# ESP32-S31 register map
Vendor: ESPRESSIF SYSTEMS (SHANGHAI) CO., LTD.; Series: ESP32 S-Series; File version: 1
CPU: RV32IMAFC r0p0, little endian, no MPU, FPU, 0 interrupt priority bits
Address unit: 32 bits
Registers are 32-bit, read-write, reset 0x0 unless marked. A register's access mark holds for its fields unless they carry their own. Offsets are from the block's base; [hi:lo] are bit positions; <NAME> marks a mode.

## GMAC (part 1 of 2) — Ethernet MAC
Base 0x20350000
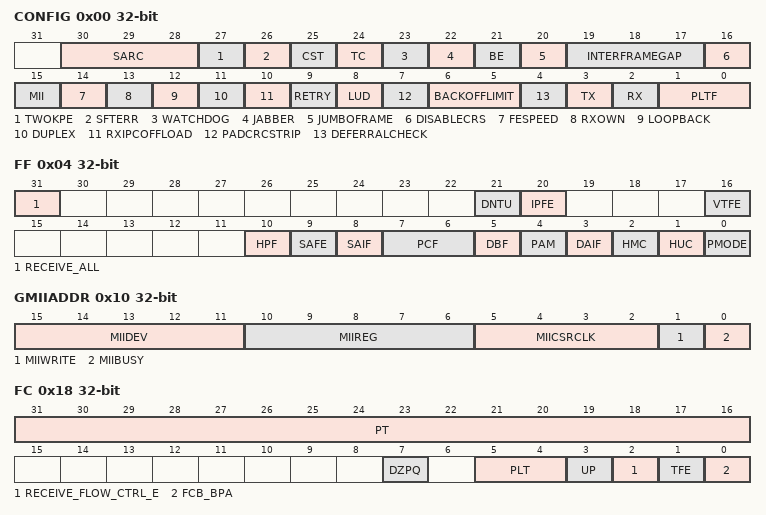
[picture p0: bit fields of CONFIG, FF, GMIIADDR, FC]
0x00 CONFIG — MAC configuration
  [30:28] SARC — Source Address Insertion or Replacement Control This field controls the source address insertion or replacement for all transmitted frames Bit 30 specifies which MAC Address register _0 or 1_ is used for source address insertion or replacement based on the values of Bits [29:28]: 2'b0x: The input signals mti_sa_ctrl_i and ati_sa_ctrl_i control the SA field generation 2'b10: If Bit 30 is set to 0, the MAC inserts the content of the MAC Address 0 registers _registers 16 and 17_ in the SA field of all transmitted frames If Bit 30 is set to 1 and the Enable MAC Address Register 1 option is selected during core configuration, the MAC inserts the content of the MAC Address 1 registers _registers 18 and 19_ in the SA field of all transmitted frames 2'b11: If Bit 30 is set to 0, the MAC replaces the content of the MAC Address 0 registers _registers 16 and 17_ in the SA field of all transmitted frames If Bit 30 is set to 1 and the Enable MAC Address Register 1 option is selected during core configuration, the MAC replaces the content of the MAC Address 1 registers _registers 18 and 19_ in the SA field of all transmitted frames Note: Changes to this field take effect only on the start of a frame If you write this register field when a frame is being transmitted, only the subsequent frame can use the updated value, that is, the current frame does not use the updated value These bits are reserved and RO when the Enable SA, VLAN, and CRC Insertion on TX feature is not selected during core configuration
  [27] TWOKPE — IEEE 8023as Support for 2K Packets When set, the MAC considers all frames, with up to 2,000 bytes length, as normal packets When Bit 20 _JE_ is not set, the MAC considers all received frames of size more than 2K bytes as Giant frames When this bit is reset and Bit 20 _JE_ is not set, the MAC considers all received frames of size more than 1,518 bytes _1,522 bytes for tagged_ as Giant frames When Bit 20 is set, setting this bit has no effect on Giant Frame status For more information about how the setting of this bit and Bit 20 impact the Giant frame status, see Table 631
  [26] SFTERR — SMII Force Transmit Error When set, this bit indicates to the PHY to force a transmit error in the SMII frame being transmitted This bit is reserved if the SMII PHY port is not selected during core configuration
  [25] CST — CRC Stripping for Type Frames When this bit is set, the last 4 bytes _FCS_ of all frames of Ether type _Length/Type field greater than or equal to 1,536_ are stripped and dropped before forwarding the frame to the application This function is not valid when the IP Checksum Engine _Type 1_ is enabled in the MAC receiver This function is valid when Type 2 Checksum Offload Engine is enabled Note: For information about how the settings of Bit 7 _ACS_ and this bit impact the frame length, see Table 632
  [24] TC — Transmit Configuration in RGMII, SGMII, or SMII When set, this bit enables the transmission of duplex mode, link speed, and link up or down information to the PHY in the RGMII, SMII, or SGMII port When this bit is reset, no such information is driven to the PHY This bit is reserved _and RO_ if the RGMII, SMII, or SGMII PHY port is not selected during core configuration The details of this feature are explained in the following sections: “Reduced Gigabit Media Independent Interface” on page 249 “Serial Media Independent Interface” on page 245 “Serial Gigabit Media Independent Interface” on page 257
  [23] WATCHDOG — Watchdog Disable When this bit is set, the MAC disables the watchdog timer on the receiver The MAC can receive frames of up to 16,383 bytes When this bit is reset, the MAC does not allow a receive frame which more than 2,048 bytes _10,240 if JE is set high_ or the value programmed in Register 55 _Watchdog Timeout Register_ The MAC cuts off any bytes received after the watchdog limit number of bytes
  [22] JABBER — Jabber Disable When this bit is set, the MAC disables the jabber timer on the transmitter The MAC can transfer frames of up to 16,383 bytes When this bit is reset, the MAC cuts off the transmitter if the application sends out more than 2,048 bytes of data _10,240 if JE is set high_ during transmission
  [21] BE — Frame Burst Enable When this bit is set, the MAC allows frame bursting during transmission in the GMII halfduplex mode This bit is reserved _and RO_ in the 10/100 Mbps only or fullduplexonly configurations
  [20] JUMBOFRAME — Jumbo Frame Enable When this bit is set, the MAC allows Jumbo frames of 9,018 bytes _9,022 bytes for VLAN tagged frames_ without reporting a giant frame error in the receive frame status
  [19:17] INTERFRAMEGAP — InterFrame Gap These bits control the minimum IFG between frames during transmission 000: 96 bit times 001: 88 bit times 010: 80 bit times 111: 40 bit times In the halfduplex mode, the minimum IFG can be configured only for 64 bit times _IFG = 100_ Lower values are not considered In the 1000Mbps mode, the minimum IFG supported is 64 bit times _and above_ in the GMACCORE configuration and 80 bit times _and above_ in other configurations When a JAM pattern is being transmitted because of backpressure activation, the MAC does not consider the minimum IFG
  [16] DISABLECRS — Disable Carrier Sense During Transmission When set high, this bit makes the MAC transmitter ignore the _G_MII CRS signal during frame transmission in the halfduplex mode This request results in no errors generated because of Loss of Carrier or No Carrier during such transmission When this bit is low, the MAC transmitter generates such errors because of Carrier Sense and can even abort the transmissions This bit is reserved _and RO_ in the fullduplexonly configurations
  [15] MII — Port Select This bit selects the Ethernet line speed 0: For 1000 Mbps operations 1: For 10 or 100 Mbps operations In 10 or 100 Mbps operations, this bit, along with FES bit, selects the exact line speed In the 10/100 Mbpsonly _always 1_ or 1000 Mbpsonly _always 0_ configurations, this bit is readonly with the appropriate value In default 10/100/1000 Mbps configuration, this bit is R_W The mac_portselect_o or mac_speed_o[1] signal reflects the value of this bit
  [14] FESPEED — Speed This bit selects the speed in the MII, RMII, SMII, RGMII, SGMII, or RevMII interface: 0: 10 Mbps 1: 100 Mbps This bit is reserved _RO_ by default and is enabled only when the parameter SPEED_SELECT = Enabled This bit generates link speed encoding when Bit 24 _TC_ is set in the RGMII, SMII, or SGMII mode This bit is always enabled for RGMII, SGMII, SMII, or RevMII interface In configurations with RGMII, SGMII, SMII, or RevMII interface, this bit is driven as an output signal _mac_speed_o[0]_ to reflect the value of this bit in the mac_speed_o signal In configurations with RMII, MII, or GMII interface, you can optionally drive this bit as an output signal _mac_speed_o[0]_ to reflect its value in the mac_speed_o signal
  [13] RXOWN — Disable Receive Own When this bit is set, the MAC disables the reception of frames when the phy_txen_o is asserted in the halfduplex mode When this bit is reset, the MAC receives all packets that are given by the PHY while transmitting This bit is not applicable if the MAC is operating in the fullduplex mode This bit is reserved _RO with default value_ if the MAC is configured for the fullduplexonly operation
  [12] LOOPBACK — Loopback Mode When this bit is set, the MAC operates in the loopback mode at GMII or MII The _G_MII Receive clock input _clk_rx_i_ is required for the loopback to work properly, because the Transmit clock is not loopedback internally
  [11] DUPLEX — Duplex Mode When this bit is set, the MAC operates in the fullduplex mode where it can transmit and receive simultaneously This bit is RO with default value of 1'b1 in the fullduplexonly configuration
  [10] RXIPCOFFLOAD — Checksum Offload When this bit is set, the MAC calculates the 16bit one’s complement of the one’s complement sum of all received Ethernet frame payloads It also checks whether the IPv4 Header checksum _assumed to be bytes 2526 or 2930 _VLAN tagged_ of the received Ethernet frame_ is correct for the received frame and gives the status in the receive status word The MAC also appends the 16bit checksum calculated for the IP header datagram payload _bytes after the IPv4 header_ and appends it to the Ethernet frame transferred to the application _when Type 2 COE is deselected_ When this bit is reset, this function is disabled When Type 2 COE is selected, this bit, when set, enables the IPv4 header checksum checking and IPv4 or IPv6 TCP, UDP, or ICMP payload checksum checking When this bit is reset, the COE function in the receiver is disabled and the corresponding PCE and IP HCE status bits _see Table 310 on page 138_ are always cleared If the IP Checksum Offload feature is not enabled during core configuration, this bit is reserved _RO with default value_
  [9] RETRY — Disable Retry When this bit is set, the MAC attempts only one transmission When a collision occurs on the GMII or MII interface, the MAC ignores the current frame transmission and reports a Frame Abort with excessive collision error in the transmit frame status When this bit is reset, the MAC attempts retries based on the settings of the BL field _Bits [6:5]_ This bit is applicable only in the halfduplex mode and is reserved _RO with default value_ in the fullduplexonly configuration
  [8] LUD — Link Up or Down This bit indicates whether the link is up or down during the transmission of configuration in the RGMII, SGMII, or SMII interface: 0: Link Down 1: Link Up This bit is reserved _RO with default value_ and is enabled when the RGMII, SGMII, or SMII interface is enabled during core configuration
  [7] PADCRCSTRIP — Automatic Pad or CRC Stripping When this bit is set, the MAC strips the Pad or FCS field on the incoming frames only if the value of the length field is less than 1,536 bytes All received frames with length field greater than or equal to 1,536 bytes are passed to the application without stripping the Pad or FCS field When this bit is reset, the MAC passes all incoming frames, without modifying them, to the Host Note: For information about how the settings of Bit 25 _CST_ and this bit impact the frame length, see Table 632
  [6:5] BACKOFFLIMIT — BackOff Limit The BackOff limit determines the random integer number _r_ of slot time delays _4,096 bit times for 1000 Mbps and 512 bit times for 10/100 Mbps_ for which the MAC waits before rescheduling a transmission attempt during retries after a collision This bit is applicable only in the halfduplex mode and is reserved _RO_ in the fullduplexonly configuration 00: k= min _n, 10_ 01: k = min _n, 8_ 10: k = min _n, 4_ 11: k = min _n, 1_ where n = retransmission attempt The random integer r takes the value in the range 0 ≤ r < 2k
  [4] DEFERRALCHECK — Deferral Check When this bit is set, the deferral check function is enabled in the MAC The MAC issues a Frame Abort status, along with the excessive deferral error bit set in the transmit frame status, when the transmit state machine is deferred for more than 24,288 bit times in the 10 or 100 Mbps mode If the MAC is configured for 1000 Mbps operation or if the Jumbo frame mode is enabled in the 10 or 100 Mbps mode, the threshold for deferral is 155,680 bits times Deferral begins when the transmitter is ready to transmit, but it is prevented because of an active carrier sense signal _CRS_ on GMII or MII The defer time is not cumulative For example, if the transmitter defers for 10,000 bit times because the CRS signal is active and then the CRS signal becomes inactive, the transmitter transmits and collision happens Because of collision, the transmitter needs to back off and then defer again after back off completion In such a scenario, the deferral timer is reset to 0 and it is restarted When this bit is reset, the deferral check function is disabled and the MAC defers until the CRS signal goes inactive This bit is applicable only in the halfduplex mode and is reserved _RO_ in the fullduplexonly configuration
  [3] TX — Transmitter Enable When this bit is set, the transmit state machine of the MAC is enabled for transmission on the GMII or MII When this bit is reset, the MAC transmit state machine is disabled after the completion of the transmission of the current frame, and does not transmit any further frames
  [2] RX — Receiver Enable When this bit is set, the receiver state machine of the MAC is enabled for receiving frames from the GMII or MII When this bit is reset, the MAC receive state machine is disabled after the completion of the reception of the current frame, and does not receive any further frames from the GMII or MII
  [1:0] PLTF — Preamble Length for Transmit frames These bits control the number of preamble bytes that are added to the beginning of every Transmit frame The preamble reduction occurs only when the MAC is operating in the fullduplex mode 2'b00: 7 bytes of preamble 2'b01: 5 bytes of preamble 2'b10: 3 bytes of preamble 2'b11: Reserved
0x04 FF — Frame filter settings
  [31] RECEIVE_ALL — Receive All When this bit is set, the MAC Receiver module passes all received frames, irrespective of whether they pass the address filter or not, to the Application The result of the SA or DA filtering is updated _pass or fail_ in the corresponding bits in the Receive Status Word When this bit is reset, the Receiver module passes only those frames to the Application that pass the SA or DA address filter
  [21] DNTU — Drop nonTCP/UDP over IP Frames When set, this bit enables the MAC to drop the nonTCP or UDP over IP frames The MAC forward only those frames that are processed by the Layer 4 filter When reset, this bit enables the MAC to forward all nonTCP or UDP over IP frames If the Layer 3 and Layer 4 Filtering feature is not selected during core configuration, this bit is reserved _RO with default value_
  [20] IPFE — Layer 3 and Layer 4 Filter Enable When set, this bit enables the MAC to drop frames that do not match the enabled Layer 3 and Layer 4 filters If Layer 3 or Layer 4 filters are not enabled for matching, this bit does not have any effect When reset, the MAC forwards all frames irrespective of the match status of the Layer 3 and Layer 4 fields If the Layer 3 and Layer 4 Filtering feature is not selected during core configuration, this bit is reserved _RO with default value_
  [16] VTFE — VLAN Tag Filter Enable When set, this bit enables the MAC to drop VLAN tagged frames that do not match the VLAN Tag comparison When reset, the MAC forwards all frames irrespective of the match status of the VLAN Tag
  [10] HPF — Hash or Perfect Filter When this bit is set, it configures the address filter to pass a frame if it matches either the perfect filtering or the hash filtering as set by the HMC or HUC bits When this bit is low and the HUC or HMC bit is set, the frame is passed only if it matches the Hash filter This bit is reserved _and RO_ if the Hash filter is not selected during core configuration
  [9] SAFE — Source Address Filter Enable When this bit is set, the MAC compares the SA field of the received frames with the values programmed in the enabled SA registers If the comparison fails, the MAC drops the frame When this bit is reset, the MAC forwards the received frame to the application with updated SAF bit of the Rx Status depending on the SA address comparison Note: According to the IEEE specification, Bit 47 of the SA is reserved and set to 0 However, in DWC_gmac, the MAC compares all 48 bits The software driver should take this into consideration while programming the MAC address registers for SA
  [8] SAIF — SA Inverse Filtering When this bit is set, the Address Check block operates in inverse filtering mode for the SA address comparison The frames whose SA matches the SA registers are marked as failing the SA Address filter When this bit is reset, frames whose SA does not match the SA registers are marked as failing the SA Address filter
  [7:6] PCF — Pass Control Frames These bits control the forwarding of all control frames _including unicast and multicast Pause frames_ 00: MAC filters all control frames from reaching the application 01: MAC forwards all control frames except Pause frames to application even if they fail the Address filter 10: MAC forwards all control frames to application even if they fail the Address Filter 11: MAC forwards control frames that pass the Address Filter The following conditions should be true for the Pause frames processing: Condition 1 : The MAC is in the fullduplex mode and flow control is enabled by setting Bit 2 _RFE_ of Register 6 _Flow Control Register_ to 1 Condition 2 : The destination address _DA_ of the received frame matches the special multicast address or the MAC Address 0 when Bit 3 _UP_ of the Register 6 _Flow Control Register_ is set Condition 3: The Type field of the received frame is 0x8808 and the OPCODE field is 0x0001 Note: This field should be set to 01 only when the Condition 1 is true, that is, the MAC is programmed to operate in the fullduplex mode and the RFE bit is enabled Otherwise, the Pause frame filtering may be inconsistent When Condition 1 is false, the Pause frames are considered as generic control frames Therefore, to pass all control frames _including Pause frames_ when the fullduplex mode and flow control is not enabled, you should set the PCF field to 10 or 11 _as required by the application_
  [5] DBF — Disable Broadcast Frames When this bit is set, the AFM module blocks all incoming broadcast frames In addition, it overrides all other filter settings When this bit is reset, the AFM module passes all received broadcast frames
  [4] PAM — Pass All Multicast When set, this bit indicates that all received frames with a multicast destination address _first bit in the destination address field is '1'_ are passed When reset, filtering of multicast frame depends on HMC bit
  [3] DAIF — DA Inverse Filtering When this bit is set, the Address Check block operates in inverse filtering mode for the DA address comparison for both unicast and multicast frames When reset, normal filtering of frames is performed
  [2] HMC — Hash Multicast When set, the MAC performs destination address filtering of received multicast frames according to the hash table When reset, the MAC performs a perfect destination address filtering for multicast frames, that is, it compares the DA field with the values programmed in DA registers If Hash Filter is not selected during core configuration, this bit is reserved _and RO_
  [1] HUC — Hash Unicast When set, the MAC performs destination address filtering of unicast frames according to the hash table When reset, the MAC performs a perfect destination address filtering for unicast frames, that is, it compares the DA field with the values programmed in DA registers If Hash Filter is not selected during core configuration, this bit is reserved _and RO_
  [0] PMODE — Promiscuous Mode When this bit is set, the Address Filter module passes all incoming frames irrespective of the destination or source address The SA or DA Filter Fails status bits of the Receive Status Word are always cleared when PR is set
0x10 GMIIADDR — PHY configuration access
  [15:11] MIIDEV — Physical Layer Address This field indicates which of the 32 possible PHY devices are being accessed For RevMII, this field gives the PHY Address of the RevMII module
  [10:6] MIIREG — GMII Register These bits select the desired GMII register in the selected PHY device For RevMII, these bits select the desired CSR register in the RevMII Registers set
  [5:2] MIICSRCLK — CSR Clock Range The CSR Clock Range selection determines the frequency of the MDC clock according to the CSR clock frequency used in your design The CSR clock corresponding to different GMAC configurations is given in Table 92 on page 564 The suggested range of CSR clock frequency applicable for each value _when Bit[5] = 0_ ensures that the MDC clock is approximately between the frequency range 10 MHz25 MHz 0000: The CSR clock frequency is 60100 MHz and the MDC clock frequency is CSR clock/42 0001: The CSR clock frequency is 100150 MHz and the MDC clock frequency is CSR clock/62 0010: The CSR clock frequency is 2035 MHz and the MDC clock frequency is CSR clock/16 0011: The CSR clock frequency is 3560 MHz and the MDC clock frequency is CSR clock/26 0100: The CSR clock frequency is 150250 MHz and the MDC clock frequency is CSR clock/102 0101: The CSR clock frequency is 250300 MHz and the MDC clock is CSR clock/124 0110, 0111: Reserved When Bit 5 is set, you can achieve higher frequency of the MDC clock than the frequency limit of 25 MHz _specified in the IEEE Std 8023_ and program a clock divider of lower value For example, when CSR clock is of 100 MHz frequency and you program these bits as 1010, then the resultant MDC clock is of 125 MHz which is outside the limit of IEEE 8023 specified range Program the following values only if the interfacing chips support faster MDC clocks 1000: CSR clock/4 1001: CSR clock/6 1010: CSR clock/8 1011: CSR clock/10 1100: CSR clock/12 1101: CSR clock/14 1110: CSR clock/16 1111: CSR clock/18 These bits are not used for accessing RevMII These bits are readonly if the RevMII interface is selected as single PHY interface
  [1] MIIWRITE — GMII Write When set, this bit indicates to the PHY or RevMII that this is a Write operation using the GMII Data register If this bit is not set, it indicates that this is a Read operation, that is, placing the data in the GMII Data register
  [0] MIIBUSY — GMII Busy This bit should read logic 0 before writing to Register 4 and Register 5 During a PHY or RevMII register access, the software sets this bit to 1’b1 to indicate that a Read or Write access is in progress Register 5 is invalid until this bit is cleared by the MAC Therefore, Register 5 _GMII Data_ should be kept valid until the MAC clears this bit during a PHY Write operation Similarly for a read operation, the contents of Register 5 are not valid until this bit is cleared The subsequent read or write operation should happen only after the previous operation is complete Because there is no acknowledgment from the PHY to MAC after a read or write operation is completed, there is no change in the functionality of this bit even when the PHY is not present
0x14 MIIDATA — PHY data read write
  [15:0] MII_DATA — GMII Data This field contains the 16bit data value read from the PHY or RevMII after a Management Read operation or the 16bit data value to be written to the PHY or RevMII before a Management Write operation
0x18 FC — Frame flow control
  [31:16] PT — Pause Time This field holds the value to be used in the Pause Time field in the transmit control frame If the Pause Time bits is configured to be doublesynchronized to the _G_MII clock domain, then consecutive writes to this register should be performed only after at least four clock cycles in the destination clock domain
  [7] DZPQ — Disable ZeroQuanta Pause When this bit is set, it disables the automatic generation of the ZeroQuanta Pause frames on the deassertion of the flowcontrol signal from the FIFO layer _MTL or external sideband flow control signal sbd_flowctrl_i/mti_flowctrl_i_ When this bit is reset, normal operation with automatic ZeroQuanta Pause frame generation is enabled
  [5:4] PLT — Pause Low Threshold This field configures the threshold of the Pause timer at which the input flow control signal mti_flowctrl_i _or sbd_flowctrl_i_ is checked for automatic retransmission of the Pause frame The threshold values should be always less than the Pause Time configured in Bits[31:16] For example, if PT = 100H _256 slottimes_, and PLT = 01, then a second Pause frame is automatically transmitted if the mti_flowctrl_i signal is asserted at 228 _256 28_ slot times after the first Pause frame is transmitted The following list provides the threshold values for different values: 00: The threshold is Pause time minus 4 slot times _PT 4 slot times_ 01: The threshold is Pause time minus 28 slot times _PT 28 slot times_ 10: The threshold is Pause time minus 144 slot times _PT 144 slot times_ 11: The threshold is Pause time minus 256 slot times _PT 256 slot times_ The slot time is defined as the time taken to transmit 512 bits _64 bytes_ on the GMII or MII interface
  [3] UP — Unicast Pause Frame Detect A pause frame is processed when it has the unique multicast address specified in the IEEE Std 8023 When this bit is set, the MAC can also detect Pause frames with unicast address of the station This unicast address should be as specified in the MAC Address0 High Register and MAC Address0 Low Register When this bit is reset, the MAC only detects Pause frames with unique multicast address Note: The MAC does not process a Pause frame if the multicast address of received frame is different from the unique multicast address
  [2] RECEIVE_FLOW_CTRL_E — Receive Flow Control Enable When this bit is set, the MAC decodes the received Pause frame and disables its transmitter for a specified _Pause_ time When this bit is reset, the decode function of the Pause frame is disabled
  [1] TFE — Transmit Flow Control Enable In the fullduplex mode, when this bit is set, the MAC enables the flow control operation to transmit Pause frames When this bit is reset, the flow control operation in the MAC is disabled, and the MAC does not transmit any Pause frames In the halfduplex mode, when this bit is set, the MAC enables the backpressure operation When this bit is reset, the backpressure feature is disabled
  [0] FCB_BPA — Flow Control Busy or Backpressure Activate This bit initiates a Pause frame in the fullduplex mode and activates the backpressure function in the halfduplex mode if the TFE bit is set In the fullduplex mode, this bit should be read as 1'b0 before writing to the Flow Control register To initiate a Pause frame, the Application must set this bit to 1'b1 During a transfer of the Control Frame, this bit continues to be set to signify that a frame transmission is in progress After the completion of Pause frame transmission, the MAC resets this bit to 1'b0 The Flow Control register should not be written to until this bit is cleared In the halfduplex mode, when this bit is set _and TFE is set_, then backpressure is asserted by the MAC During backpressure, when the MAC receives a new frame, the transmitter starts sending a JAM pattern resulting in a collision This control register bit is logically ORed with the mti_flowctrl_i input signal for the backpressure function When the MAC is configured for the fullduplex mode, the BPA is automatically disabled
